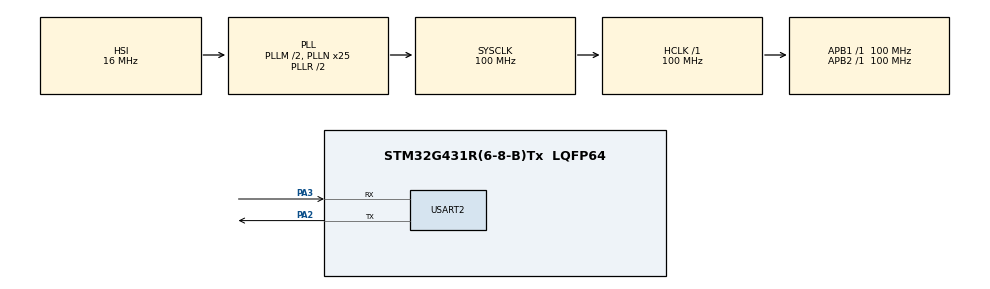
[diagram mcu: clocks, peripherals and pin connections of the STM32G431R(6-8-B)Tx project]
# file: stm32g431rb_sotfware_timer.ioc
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Mcu.Family=STM32G4
Mcu.Name=STM32G431R(6-8-B)Tx
Mcu.Package=LQFP64
NVIC.PriorityGroup=NVIC_PRIORITYGROUP_4
NVIC.TIM7_IRQn=true\:0\:0\:false\:false\:true\:true\:true\:true
PA2.Mode=Asynchronous
PA2.Signal=USART2_TX
PA3.Mode=Asynchronous
PA3.Signal=USART2_RX
ProjectManager.HeapSize=0x200
ProjectManager.StackSize=0x400
ProjectManager.TargetToolchain=STM32CubeIDE
RCC.ADC12Freq_Value=100000000
RCC.AHBFreq_Value=100000000
RCC.APB1Freq_Value=100000000
RCC.APB1TimFreq_Value=100000000
RCC.APB2Freq_Value=100000000
RCC.APB2TimFreq_Value=100000000
RCC.CortexFreq_Value=100000000
RCC.EXTERNAL_CLOCK_VALUE=12288000
RCC.HCLKFreq_Value=100000000
RCC.HSE_VALUE=8000000
RCC.HSI48_VALUE=48000000
RCC.HSI_VALUE=16000000
RCC.LSE_VALUE=32768
RCC.PLLM=RCC_PLLM_DIV2
RCC.PLLN=25
RCC.SYSCLKFreq_VALUE=100000000
RCC.SYSCLKSource=RCC_SYSCLKSOURCE_PLLCLK
RCC.USBFreq_Value=100000000
RCC.VCOOutputFreq_Value=200000000
TIM7.PeriodNoDither=9999
TIM7.Prescaler=99
USART2.VirtualMode-Asynchronous=VM_ASYNC
VP_SYS_VS_DBSignals.Mode=DisableDeadBatterySignals
VP_TIM7_VS_ClockSourceINT.Mode=Enable_Timer
board=custom

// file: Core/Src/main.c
/* USER CODE BEGIN Header */
/**
  ******************************************************************************
  * @file           : main.c
  * @brief          : Main program body
  ******************************************************************************
  * @attention
  *
  * Copyright (c) 2023 STMicroelectronics.
  * All rights reserved.
  *
  * This software is licensed under terms that can be found in the LICENSE file
  * in the root directory of this software component.
  * If no LICENSE file comes with this software, it is provided AS-IS.
  *
  ******************************************************************************
  */
/* USER CODE END Header */
#include "main.h"

/* USER CODE BEGIN Includes */
#include <stdio.h>
#include "timer.h"
/* USER CODE END Includes */

UART_HandleTypeDef huart2;

void SystemClock_Config(void);
static void MX_GPIO_Init(void);
static void MX_TIM7_Init(void);
static void MX_USART2_UART_Init(void);

/* USER CODE BEGIN 0 */
int _write(int file, char *ptr, int len)
{
  HAL_UART_Transmit(&huart2, (uint8_t *)ptr, len, HAL_MAX_DELAY);
  return len;
}

void process1(int8_t timer_id, uint32_t param1)
{
  printf("process1 \r\n");
}

void process2(int8_t timer_id, uint32_t param1)
{
  printf("process2 \r\n");
}

void process3(int8_t timer_id, uint32_t param1)
{

  printf("one shot process3 !!! \r\n");
}
/* USER CODE END 0 */

int main(void)
{

  /* MCU Configuration--------------------------------------------------------*/

  /* Reset of all peripherals, Initializes the Flash interface and the Systick. */
  HAL_Init();

  /* Configure the system clock */
  SystemClock_Config();

  /* Initialize all configured peripherals */
  MX_GPIO_Init();
  MX_TIM7_Init();
  MX_USART2_UART_Init();
  /* USER CODE BEGIN 2 */
  LL_TIM_SetCounter(TIM7, 0);
  LL_TIM_EnableIT_UPDATE(TIM7);
  LL_TIM_EnableCounter(TIM7);
  /* USER CODE END 2 */

  /* Infinite loop */
  /* USER CODE BEGIN WHILE */
  register_timer(TIMER_100ms, process1, PERIODIC);
  register_timer(TIMER_1s, process2, PERIODIC);
  register_timer(TIMER_3s, process3, ONE_SHOT);

  while (1)
  {
    process_timer(0, 0);
    /* USER CODE END WHILE */

  }
}

void SystemClock_Config(void)
{
  RCC_OscInitTypeDef RCC_OscInitStruct = {0};
  RCC_ClkInitTypeDef RCC_ClkInitStruct = {0};

  /** Configure the main internal regulator output voltage
  */
  HAL_PWREx_ControlVoltageScaling(PWR_REGULATOR_VOLTAGE_SCALE1);

  /** Initializes the RCC Oscillators according to the specified parameters
  * in the RCC_OscInitTypeDef structure.
  */
  RCC_OscInitStruct.OscillatorType = RCC_OSCILLATORTYPE_HSI;
  RCC_OscInitStruct.HSIState = RCC_HSI_ON;
  RCC_OscInitStruct.HSICalibrationValue = RCC_HSICALIBRATION_DEFAULT;
  RCC_OscInitStruct.PLL.PLLState = RCC_PLL_ON;
  RCC_OscInitStruct.PLL.PLLSource = RCC_PLLSOURCE_HSI;
  RCC_OscInitStruct.PLL.PLLM = RCC_PLLM_DIV2;
  RCC_OscInitStruct.PLL.PLLN = 25;
  RCC_OscInitStruct.PLL.PLLP = RCC_PLLP_DIV2;
  RCC_OscInitStruct.PLL.PLLQ = RCC_PLLQ_DIV2;
  RCC_OscInitStruct.PLL.PLLR = RCC_PLLR_DIV2;
  if (HAL_RCC_OscConfig(&RCC_OscInitStruct) != HAL_OK)
  {
    Error_Handler();
  }

  /** Initializes the CPU, AHB and APB buses clocks
  */
  RCC_ClkInitStruct.ClockType = RCC_CLOCKTYPE_HCLK|RCC_CLOCKTYPE_SYSCLK
                              |RCC_CLOCKTYPE_PCLK1|RCC_CLOCKTYPE_PCLK2;
  RCC_ClkInitStruct.SYSCLKSource = RCC_SYSCLKSOURCE_PLLCLK;
  RCC_ClkInitStruct.AHBCLKDivider = RCC_SYSCLK_DIV1;
  RCC_ClkInitStruct.APB1CLKDivider = RCC_HCLK_DIV1;
  RCC_ClkInitStruct.APB2CLKDivider = RCC_HCLK_DIV1;

  if (HAL_RCC_ClockConfig(&RCC_ClkInitStruct, FLASH_LATENCY_3) != HAL_OK)
  {
    Error_Handler();
  }
}

static void MX_TIM7_Init(void)
{

  LL_TIM_InitTypeDef TIM_InitStruct = {0};

  /* Peripheral clock enable */
  LL_APB1_GRP1_EnableClock(LL_APB1_GRP1_PERIPH_TIM7);

  /* TIM7 interrupt Init */
  NVIC_SetPriority(TIM7_IRQn, NVIC_EncodePriority(NVIC_GetPriorityGrouping(),0, 0));
  NVIC_EnableIRQ(TIM7_IRQn);

  TIM_InitStruct.Prescaler = 99;
  TIM_InitStruct.CounterMode = LL_TIM_COUNTERMODE_UP;
  TIM_InitStruct.Autoreload = 9999;
  LL_TIM_Init(TIM7, &TIM_InitStruct);
  LL_TIM_DisableARRPreload(TIM7);
  LL_TIM_SetTriggerOutput(TIM7, LL_TIM_TRGO_RESET);
  LL_TIM_DisableMasterSlaveMode(TIM7);

}

static void MX_USART2_UART_Init(void)
{

  huart2.Instance = USART2;
  huart2.Init.BaudRate = 115200;
  huart2.Init.WordLength = UART_WORDLENGTH_8B;
  huart2.Init.StopBits = UART_STOPBITS_1;
  huart2.Init.Parity = UART_PARITY_NONE;
  huart2.Init.Mode = UART_MODE_TX_RX;
  huart2.Init.HwFlowCtl = UART_HWCONTROL_NONE;
  huart2.Init.OverSampling = UART_OVERSAMPLING_16;
  huart2.Init.OneBitSampling = UART_ONE_BIT_SAMPLE_DISABLE;
  huart2.Init.ClockPrescaler = UART_PRESCALER_DIV1;
  huart2.AdvancedInit.AdvFeatureInit = UART_ADVFEATURE_NO_INIT;
  if (HAL_UART_Init(&huart2) != HAL_OK)
  {
    Error_Handler();
  }
  if (HAL_UARTEx_SetTxFifoThreshold(&huart2, UART_TXFIFO_THRESHOLD_1_8) != HAL_OK)
  {
    Error_Handler();
  }
  if (HAL_UARTEx_SetRxFifoThreshold(&huart2, UART_RXFIFO_THRESHOLD_1_8) != HAL_OK)
  {
    Error_Handler();
  }
  if (HAL_UARTEx_DisableFifoMode(&huart2) != HAL_OK)
  {
    Error_Handler();
  }

}

static void MX_GPIO_Init(void)
{

  /* GPIO Ports Clock Enable */
  __HAL_RCC_GPIOA_CLK_ENABLE();

}

void Error_Handler(void)
{
  __disable_irq();
  while (1)
  {
  }
}
